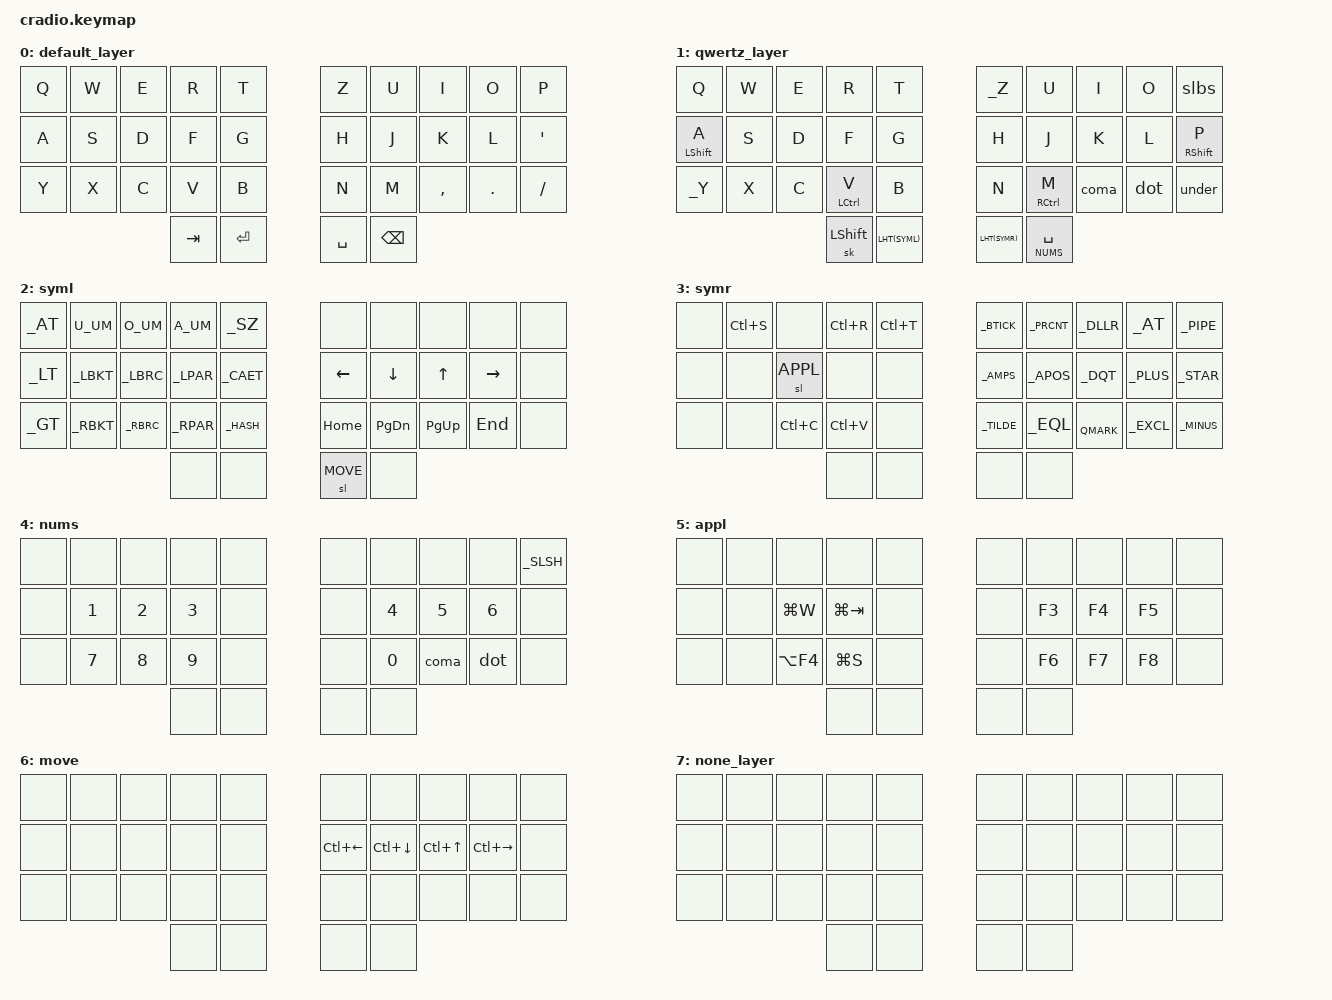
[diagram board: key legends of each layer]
// Copyright (c) 2022 The ZMK Contributors
// SPDX-License-Identifier: MIT

#include <behaviors.dtsi>
#include <dt-bindings/zmk/outputs.h>
#include <dt-bindings/zmk/keys.h>
#include <dt-bindings/zmk/bt.h>
#include "keys_de.h"

#define DEFAULT 0
#define QWER    1
#define SYML    2
#define SYMR    3
#define NUMS    4
#define APPL    5
#define MOVE    6
#define NONE    7

&key_repeat {
    usage-pages = <HID_USAGE_KEY HID_USAGE_CONSUMER>;
};

&kscan0 {
    input-gpios
    = <&pro_micro  4 (GPIO_ACTIVE_LOW | GPIO_PULL_UP)>
    , <&pro_micro  3 (GPIO_ACTIVE_LOW | GPIO_PULL_UP)>
    , <&pro_micro  2 (GPIO_ACTIVE_LOW | GPIO_PULL_UP)>
    , <&pro_micro  0 (GPIO_ACTIVE_LOW | GPIO_PULL_UP)>
    , <&pro_micro  1 (GPIO_ACTIVE_LOW | GPIO_PULL_UP)>

    , <&pro_micro  9 (GPIO_ACTIVE_LOW | GPIO_PULL_UP)>
    , <&pro_micro  8 (GPIO_ACTIVE_LOW | GPIO_PULL_UP)>
    , <&pro_micro  7 (GPIO_ACTIVE_LOW | GPIO_PULL_UP)>
    , <&pro_micro  6 (GPIO_ACTIVE_LOW | GPIO_PULL_UP)>
    , <&pro_micro  5 (GPIO_ACTIVE_LOW | GPIO_PULL_UP)>

    , <&pro_micro 10 (GPIO_ACTIVE_LOW | GPIO_PULL_UP)>
    , <&pro_micro 16 (GPIO_ACTIVE_LOW | GPIO_PULL_UP)>
    , <&pro_micro 14 (GPIO_ACTIVE_LOW | GPIO_PULL_UP)>
    , <&pro_micro 15 (GPIO_ACTIVE_LOW | GPIO_PULL_UP)>
    , <&pro_micro 18 (GPIO_ACTIVE_LOW | GPIO_PULL_UP)>

    , <&pro_micro 21 (GPIO_ACTIVE_LOW | GPIO_PULL_UP)>
    , <&pro_micro 20 (GPIO_ACTIVE_LOW | GPIO_PULL_UP)>
    ;
};


#define LHT(layer) &mo_tog layer layer   // Macro to apply momentary-layer-on-hold/toggle-layer-on-tap to a specific layer

/ {
    behaviors {
        ht: hold_tap {
            label = "hold_tap";
            compatible = "zmk,behavior-hold-tap";
            #binding-cells = <2>;
            flavor = "balanced";
            tapping-term-ms = <250>;
            quick-tap-ms = <50>;
            bindings = <&kp>, <&kp>;
        };
        mo_tog: behavior_mo_tog {
            compatible = "zmk,behavior-hold-tap";
            #binding-cells = <2>;
            flavor = "hold-preferred";
            tapping-term-ms = <200>;
            bindings = <&mo>, <&sl>;
        };
        slbs: slash_backslash {
            compatible = "zmk,behavior-mod-morph";
            #binding-cells = <0>;
            bindings = <&kp _SLSH>, <&kp _BSLH>;
            mods = <(MOD_LSFT|MOD_RSFT)>;
        };
        under: under_minus {
            compatible = "zmk,behavior-mod-morph";
            #binding-cells = <0>;
            bindings = <&kp _UNDR>, <&kp _MINUS>;
            mods = <(MOD_LSFT|MOD_RSFT)>;
        };
        coma: comma_question {
            compatible = "zmk,behavior-mod-morph";
            #binding-cells = <0>;
            bindings = <&kp _COMA>, <&kp _QMARK>;
            mods = <(MOD_LSFT|MOD_RSFT)>;
        };
        dot: dot_exmark {
            compatible = "zmk,behavior-mod-morph";
            #binding-cells = <0>;
            bindings = <&kp _DOT>, <&kp _EXCL>;
            mods = <(MOD_LSFT|MOD_RSFT)>;
        };
    };
    combos {
        compatible = "zmk,combos";
        combo_toqwer {
            timeout-ms = <50>;
            key-positions = <0 1 2 3>;
            bindings = <&tog 1>;
            // layers = <0,1>;
        };
        // combo_bt_clear {
        //     timeout-ms = <50>;
        //     key-positions = <10 11 12 13>;
        //     bindings = <&bt BT_CLR>;
        //     // layers = <1>;
        // };
        combo_bt_clear_all {
            timeout-ms = <50>;
            key-positions = <11 12 13 14>;
            bindings = <&bt BT_CLR_ALL>;
            // layers = <1>;
        };
        combo_bt_next {
            timeout-ms = <50>;
            key-positions = <10 11 12 13>;
            bindings = <&bt BT_NXT>;
        };
        combo_bootloader {
            timeout-ms = <50>;
            key-positions = <1 2 3 4>;
            bindings = <&bootloader>;
            // layers = <1>;
        };
        combo_bootloader_left {
            timeout-ms = <50>;
            key-positions = <5 6 7 8>;
            bindings = <&bootloader>;
            // layers = <1>;
        };
        combo_reset {
            timeout-ms = <50>;
            key-positions = <0 1 2 3 4>;
            bindings = <&sys_reset>;
            // layers = <1>;
        };
        combo_reset_left {
            timeout-ms = <50>;
            key-positions = <5 6 7 8 9>;
            bindings = <&sys_reset>;
            // layers = <1>;
        };
        // combo_bluetooth_toggle {
        //     timeout-ms = <50>;
        //     // key-positions = <21 22 23>;
        //     key-positions = <10 11 12 13>;
        //     bindings = <&out OUT_BLE>;
        // };
        // todo: use macro approach from website
        combo_esc {
            timeout-ms = <50>;
            key-positions = <12 13>;
            bindings = <&kp ESC>;
            layers = <1 2 3 4>;
        };
        combo_tab {
            timeout-ms = <50>;
            key-positions = <22 23>;
            bindings = <&kp TAB>;
            layers = <1 2 3 4>;
        };
        combo_bksp {
            timeout-ms = <50>;
            key-positions = <16 17>;
            bindings = <&kp BKSP>;
            layers = <1 2 3 4>;
        };
        combo_delword {
            timeout-ms = <50>;
            key-positions = <16 17 18>;
            bindings = <&kp LC(BKSP)>;
            layers = <1 2 3 4>;
        };
        combo_ret {
            timeout-ms = <50>;
            key-positions = <26 27>;
            bindings = <&kp RET>;
            layers = <1 2 3 4>;
        };
        combo_colon {
            timeout-ms = <50>;
            key-positions = <17 26>;
            bindings = <&kp _COLON>;
            layers = <1 2 3 4>;
        };
        combo_semicolon {
            timeout-ms = <50>;
            key-positions = <16 27>;
            bindings = <&kp _SEMI>;
            layers = <1 2 3 4>;
        };
    };
    keymap {
        compatible = "zmk,keymap";
        default_layer {
            bindings = <
        //╭──────────┬──────────┬──────────┬──────────┬──────────╮   ╭──────────┬──────────┬──────────┬──────────┬──────────╮
        //│  Q       │  W       │  E       │  R       │  T       │   │  Z       │  U       │  I       │  O       │  P       │
            &kp Q      &kp W      &kp E      &kp R      &kp T          &kp Z      &kp U      &kp I      &kp O      &kp P
        //├──────────┼──────────┼──────────┼──────────┼──────────┤   ├──────────┼──────────┼──────────┼──────────┼──────────┤
        //│  A       │  S       │  D       │  F       │  G       │   │  H       │  J       │  K       │  L       │ '        │
            &kp A       &kp S      &kp D      &kp F      &kp G          &kp H      &kp J      &kp K      &kp L     &kp SQT
        //├──────────┼──────────┼──────────┼──────────┼──────────┤   ├──────────┼──────────┼──────────┼──────────┼──────────┤
        //│  Y       │  X       │  C       │  V       │  B       │   │  N       │  M       │ ,        │ .        │ /        │
            &kp Y      &kp X      &kp C      &kp V      &kp B          &kp N      &kp M      &kp COMMA  &kp DOT    &kp FSLH
        //╰──────────┴──────────┴──────────┼──────────┼──────────┤   ├──────────┼──────────┼──────────┴──────────┴──────────╯
                                             &kp TAB    &kp ENTER      &kp SPACE  &kp BSPC
        //                                 ╰──────────┴──────────╯   ╰──────────┴──────────╯
            >;
        };
        qwertz_layer {
            bindings = <
        //╭──────────┬──────────┬──────────┬──────────┬──────────╮   ╭──────────┬──────────┬──────────┬──────────┬──────────╮
        //│  Q       │  W       │  E       │  R       │  T       │   │  Z       │  U       │  I       │  O       │  /       │
            &kp Q      &kp W      &kp E      &kp R      &kp T          &kp _Z     &kp U      &kp I      &kp O      &slbs 
        //├──────────┼──────────┼──────────┼──────────┼──────────┤   ├──────────┼──────────┼──────────┼──────────┼──────────┤
        //│  A       │  S       │  D       │  F       │  G       │   │  H       │  J       │  K       │  L       │ P        │
          &ht LSHIFT A &kp S      &kp D      &kp F      &kp G          &kp H      &kp J      &kp K      &kp L      &ht RSHIFT P
        //├──────────┼──────────┼──────────┼──────────┼──────────┤   ├──────────┼──────────┼──────────┼──────────┼──────────┤
        //│  Y       │  X       │  C       │  V       │  B       │   │  N       │  M       │ ,        │ .        │ _        │
            &kp _Y      &kp X      &kp C   &ht LCTRL V   &kp B          &kp N   &ht RCTRL M  &coma      &dot       &under
        //╰──────────┴──────────┴──────────┼──────────┼──────────┤   ├──────────┼──────────┼──────────┴──────────┴──────────╯
                                             //&key_repeat LHT(SYML)      LHT(SYMR)  &lt NUMS SPACE
                                             &sk LSHIFT LHT(SYML)      LHT(SYMR)  &lt NUMS SPACE
        //                                 ╰──────────┴──────────╯   ╰──────────┴──────────╯
            >;
        };
        syml {
            bindings = <
        //╭──────────┬──────────┬──────────┬──────────┬──────────╮   ╭──────────┬──────────┬──────────┬──────────┬──────────╮
        //│  @       │  ü       │  ö       │  ä       │  ß       │   │          │          │          │          │          │
            &kp _AT     &kp U_UM   &kp O_UM   &kp A_UM   &kp _SZ        &none      &none      &none      &none      &none 
        //├──────────┼──────────┼──────────┼──────────┼──────────┤   ├──────────┼──────────┼──────────┼──────────┼──────────┤   
        //│  <       │  [       │  {       │  (       │  ^       │   │          │          │          │          │          │
            &kp _LT     &kp _LBKT  &kp _LBRC  &kp _LPAR  &kp _CAET      &kp LEFT   &kp DOWN   &kp UP     &kp RIGHT  &none 
        //├──────────┼──────────┼──────────┼──────────┼──────────┤   ├──────────┼──────────┼──────────┼──────────┼──────────┤
        //│  >       │  ]       │  }       │  )       │  #       │   │          │          │          │          │          │
            &kp _GT     &kp _RBKT  &kp _RBRC  &kp _RPAR  &kp _HASH      &kp HOME   &kp PG_DN  &kp PG_UP  &kp END    &none 
        //╰──────────┴──────────┴──────────┼──────────┼──────────┤   ├──────────┼──────────┼──────────┴──────────┴──────────╯
                                              &none      &none          &sl MOVE  &none
        //                                 ╰──────────┴──────────╯   ╰──────────┴──────────╯
            >;
        };
        symr {
            bindings = <
        //╭──────────┬──────────┬──────────┬──────────┬──────────╮   ╭──────────┬──────────┬──────────┬──────────┬──────────╮
        //│          │  ctl_s   │          │  ctl_r   │  crl_t   │   │  `       │  %       │  $       │  @       │  |       │
            &none       &kp LC(S)  &none      &kp LC(R)  &kp LC(T)       &kp _BTICK &kp _PRCNT &kp _DLLR  &kp _AT    &kp _PIPE 
        //├──────────┼──────────┼──────────┼──────────┼──────────┤   ├──────────┼──────────┼──────────┼──────────┼──────────┤
        //│          │          │  to app  │          │          │   │  &       │  '       │  "       │  +       │  *       │
            &none       &none      &sl APPL   &none      &none          &kp _AMPS  &kp _APOS  &kp _DQT   &kp _PLUS  &kp _STAR
        //├──────────┼──────────┼──────────┼──────────┼──────────┤   ├──────────┼──────────┼──────────┼──────────┼──────────┤
        //│          │          │  ctl_c   │  clt_v   │          │   │  ~       │  =       │  ?       │  !       │  -       │
            &none       &none      &kp LC(C)  &kp LC(V)  &none          &kp _TILDE &kp _EQL   &kp _QMARK &kp _EXCL  &kp _MINUS
        //╰──────────┴──────────┴──────────┼──────────┼──────────┤   ├──────────┼──────────┼──────────┴──────────┴──────────╯
                                              &none      &none          &none      &none 
        //                                 ╰──────────┴──────────╯   ╰──────────┴──────────╯
            >;
        };
        nums {
            bindings = <
        //╭──────────┬──────────┬──────────┬──────────┬──────────╮   ╭──────────┬──────────┬──────────┬──────────┬──────────╮
        //│          │          │          │          │          │   │          │          │          │          │  /       │
             &none      &none      &none      &none      &none          &none      &none      &none      &none      &kp _SLSH
        //├──────────┼──────────┼──────────┼──────────┼──────────┤   ├──────────┼──────────┼──────────┼──────────┼──────────┤
        //│  A       │  1       │  2       │  3       │          │   │          │  4       │  5       │  6       │          │
             &none      &kp N1     &kp N2     &kp N3     &none          &none      &kp N4     &kp N5     &kp N6     &none
        //├──────────┼──────────┼──────────┼──────────┼──────────┤   ├──────────┼──────────┼──────────┼──────────┼──────────┤
        //│  Y       │  7       │  8       │  9       │          │   │          │  0       │  ,       │ .        │          │
             &none      &kp N7     &kp N8     &kp N9     &none          &none      &kp N0     &coma     &dot        &none 
        //╰──────────┴──────────┴──────────┼──────────┼──────────┤   ├──────────┼──────────┼──────────┴──────────┴──────────╯
                                              &none      &none          &none      &none 
        //                                 ╰──────────┴──────────╯   ╰──────────┴──────────╯
            >;
        };
        appl {
            bindings = <
        //╭──────────┬──────────┬──────────┬──────────┬──────────╮   ╭──────────┬──────────┬──────────┬──────────┬──────────╮
        //│          │          │          │          │          │   │          │          │          │          │          │
            &none       &none      &none      &none      &none          &none      &none      &none      &none      &none 
        //├──────────┼──────────┼──────────┼──────────┼──────────┤   ├──────────┼──────────┼──────────┼──────────┼──────────┤
        //│          │          │          │          │          │   │          │          │          │          │          │
            &none       &none      &kp LG(W) &kp LG(TAB) &none          &none      &kp F3     &kp F4     &kp F5     &none 
        //├──────────┼──────────┼──────────┼──────────┼──────────┤   ├──────────┼──────────┼──────────┼──────────┼──────────┤
        //│          │          │          │          │          │   │          │          │          │          │          │
            &none       &none     &kp LA(F4) &kp LG(S)   &none          &none      &kp F6     &kp F7     &kp F8     &none
        //╰──────────┴──────────┴──────────┼──────────┼──────────┤   ├──────────┼──────────┼──────────┴──────────┴──────────╯
                                              &none      &none          &none      &none 
        //                                 ╰──────────┴──────────╯   ╰──────────┴──────────╯
            >;
        };
        move {
            bindings = <
        //╭──────────┬──────────┬──────────┬──────────┬──────────╮   ╭──────────┬──────────┬──────────┬──────────┬──────────╮
        //│          │          │          │          │          │   │          │          │          │          │          │
            &none       &none      &none      &none      &none          &none      &none      &none      &none      &none 
        //├──────────┼──────────┼──────────┼──────────┼──────────┤   ├──────────┼──────────┼──────────┼──────────┼──────────┤
        //│          │          │          │          │          │   │          │          │          │          │          │
            &none       &none      &none      &none      &none       &kp LC(LEFT) &kp LC(DOWN) &kp LC(UP) &kp LC(RIGHT) &none 
        //├──────────┼──────────┼──────────┼──────────┼──────────┤   ├──────────┼──────────┼──────────┼──────────┼──────────┤
        //│          │          │          │          │          │   │          │          │          │          │          │
            &none       &none      &none      &none      &none          &none      &none     &none       &none      &none
        //╰──────────┴──────────┴──────────┼──────────┼──────────┤   ├──────────┼──────────┼──────────┴──────────┴──────────╯
                                              &none      &none          &none      &none 
        //                                 ╰──────────┴──────────╯   ╰──────────┴──────────╯
            >;
        };
        none_layer {
            bindings = <
        //╭──────────┬──────────┬──────────┬──────────┬──────────╮   ╭──────────┬──────────┬──────────┬──────────┬──────────╮
        //│          │          │          │          │          │   │          │          │          │          │          │
            &none       &none      &none      &none      &none          &none      &none      &none      &none      &none 
        //├──────────┼──────────┼──────────┼──────────┼──────────┤   ├──────────┼──────────┼──────────┼──────────┼──────────┤
        //│          │          │          │          │          │   │          │          │          │          │          │
            &none       &none      &none      &none      &none          &none      &none      &none      &none      &none 
        //├──────────┼──────────┼──────────┼──────────┼──────────┤   ├──────────┼──────────┼──────────┼──────────┼──────────┤
        //│          │          │          │          │          │   │          │          │          │          │          │
            &none       &none      &none      &none      &none          &none      &none     &none       &none      &none
        //╰──────────┴──────────┴──────────┼──────────┼──────────┤   ├──────────┼──────────┼──────────┴──────────┴──────────╯
                                              &none      &none          &none      &none 
        //                                 ╰──────────┴──────────╯   ╰──────────┴──────────╯
            >;
        };
    };
};
